AUTOSAR XML (schema 00050)
package /Components
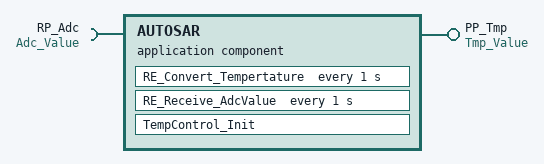
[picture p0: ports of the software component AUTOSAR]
  application sw component type AUTOSAR
    require port RP_Adc: nonqueued-receiver-com-spec{data-element=Adc_Value, init-value=0}, required-interface=Adc_Value
    provide port PP_Tmp: nonqueued-sender-com-spec{data-element=Tmp_Value, init-value=0}, provided-interface=Tmp_Value
    behavior untitled_IB: handle-termination-and-restart=NO-SUPPORT
      timing event Event: start-on-event=RE_Convert_Tempertature, period=1
      timing event Event1: start-on-event=RE_Receive_AdcValue, period=1
      implicit-inter-runnable-variables:
        data adc: category=VALUE, sw-calibration-access=READ-ONLY, type=UInt16, init-value=0
      runnable RE_Convert_Tempertature
        data-write-access:
          access OUT_PP_Tmp_Tmp_Value: accessed-variable=PP_Tmp.Tmp_Value
        read-local-variables:
          access RV_adc: accessed-variable=adc
      runnable RE_Receive_AdcValue
        data-read-access:
          access IN_RP_Adc_Adc_Value: accessed-variable=RP_Adc.Adc_Value
        written-local-variables:
          access WV_adc: accessed-variable=adc
      runnable TempControl_Init
